# ESP32-S31 register map
Vendor: ESPRESSIF SYSTEMS (SHANGHAI) CO., LTD.; Series: ESP32 S-Series; File version: 1
CPU: RV32IMAFC r0p0, little endian, no MPU, FPU, 0 interrupt priority bits
Address unit: 32 bits
Registers are 32-bit, read-write, reset 0x0 unless marked. A register's access mark holds for its fields unless they carry their own. Offsets are from the block's base; [hi:lo] are bit positions; {n}, {i} and the like mark numbered series.

## SPI0 (part 1 of 2) — SPI (Serial Peripheral Interface) Controller 0
Base 0x20500000
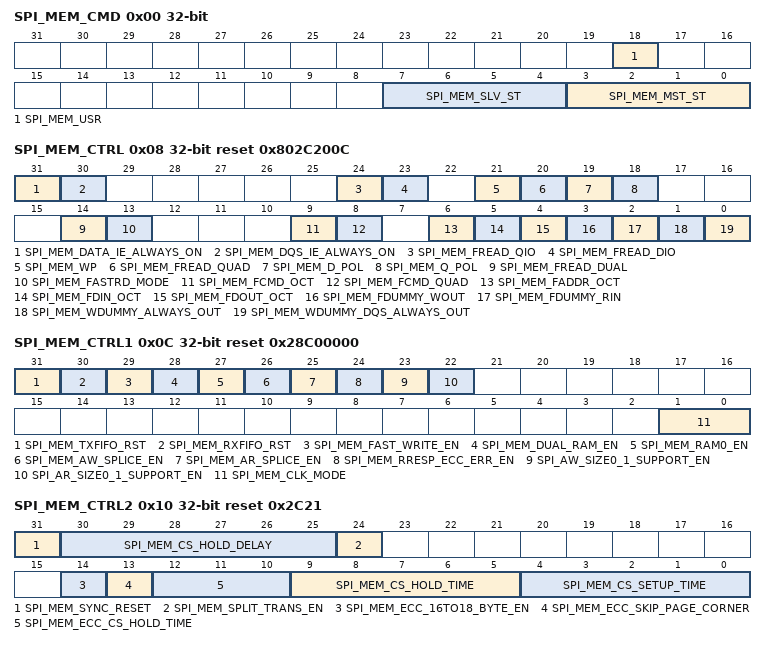
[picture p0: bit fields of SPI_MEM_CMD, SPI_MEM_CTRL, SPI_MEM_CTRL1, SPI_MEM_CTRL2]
0x00 SPI_MEM_CMD ro — SPI0 FSM status register
  [18] SPI_MEM_USR — SPI0 USR_CMD start bit, only used when SPI_MEM_AXI_REQ_EN is cleared. An operation will be triggered when the bit is set. The bit will be cleared once the operation done.1: enable 0: disable.
  [7:4] SPI_MEM_SLV_ST — The current status of SPI0 slave FSM: mspi_st. 0: idle state, 1: preparation state, 2: send command state, 3: send address state, 4: wait state, 5: read data state, 6:write data state, 7: done state, 8: read data end state.
  [3:0] SPI_MEM_MST_ST — The current status of SPI0 master FSM: spi0_mst_st. 0: idle state, 1:SPI0_GRANT , 2: program/erase suspend state, 3: SPI0 read data state, 4: wait cache/EDMA sent data is stored in SPI0 TX FIFO, 5: SPI0 write data state.
0x08 SPI_MEM_CTRL reset 0x802C200C — SPI0 control register.
  [31] SPI_MEM_DATA_IE_ALWAYS_ON — When accesses to flash, 1: the IE signals of pads connected to SPI_IO[7:0] are always 1. 0: Others.
  [30] SPI_MEM_DQS_IE_ALWAYS_ON — When accesses to flash, 1: the IE signals of pads connected to SPI_DQS are always 1. 0: Others.
  [24] SPI_MEM_FREAD_QIO — In the read operations address phase and read-data phase apply 4 signals. 1: enable 0: disable.
  [23] SPI_MEM_FREAD_DIO — In the read operations address phase and read-data phase apply 2 signals. 1: enable 0: disable.
  [21] SPI_MEM_WP — Write protect signal output when SPI is idle. 1: output high, 0: output low.
  [20] SPI_MEM_FREAD_QUAD — In the read operations read-data phase apply 4 signals. 1: enable 0: disable.
  [19] SPI_MEM_D_POL — The bit is used to set MOSI line polarity, 1: high 0, low
  [18] SPI_MEM_Q_POL — The bit is used to set MISO line polarity, 1: high 0, low
  [14] SPI_MEM_FREAD_DUAL — In the read operations, read-data phase apply 2 signals. 1: enable 0: disable.
  [13] SPI_MEM_FASTRD_MODE — This bit enable the bits: SPI_MEM_FREAD_QIO, SPI_MEM_FREAD_DIO, SPI_MEM_FREAD_QOUT and SPI_MEM_FREAD_DOUT. 1: enable 0: disable.
  [9] SPI_MEM_FCMD_OCT — Apply 8 signals during command phase 1:enable 0: disable
  [8] SPI_MEM_FCMD_QUAD — Apply 4 signals during command phase 1:enable 0: disable
  [6] SPI_MEM_FADDR_OCT — Apply 8 signals during address phase 1:enable 0: disable
  [5] SPI_MEM_FDIN_OCT — Apply 8 signals during read-data phase 1:enable 0: disable
  [4] SPI_MEM_FDOUT_OCT — Apply 8 signals during write-data phase 1:enable 0: disable
  [3] SPI_MEM_FDUMMY_WOUT — In an MSPI write data transfer when accesses to flash, the level of SPI_IO[7:0] is output by the MSPI controller in the second half part of dummy phase. It is used to pre-drive flash.
  [2] SPI_MEM_FDUMMY_RIN — In an MSPI read data transfer when accesses to flash, the level of SPI_IO[7:0] is output by the MSPI controller in the first half part of dummy phase. It is used to mask invalid SPI_DQS in the half part of dummy phase.
  [1] SPI_MEM_WDUMMY_ALWAYS_OUT — In the dummy phase of an MSPI write data transfer when accesses to flash, the level of SPI_IO[7:0] is output by the MSPI controller.
  [0] SPI_MEM_WDUMMY_DQS_ALWAYS_OUT — In the dummy phase of an MSPI write data transfer when accesses to flash, the level of SPI_DQS is output by the MSPI controller.
0x0C SPI_MEM_CTRL1 access per field reset 0x28C00000 — SPI0 control1 register.
  [31] SPI_MEM_TXFIFO_RST wo — The synchronous reset signal for SPI0 TX AFIFO and all the AES_MSPI SYNC FIFO to send signals to AXI. Set this bit to reset these FIFO.
  [30] SPI_MEM_RXFIFO_RST wo — The synchronous reset signal for SPI0 RX AFIFO and all the AES_MSPI SYNC FIFO to receive signals from AXI. Set this bit to reset these FIFO.
  [29] SPI_MEM_FAST_WRITE_EN rw — Set this bit to write data faster, do not wait write data has been stored in tx_bus_fifo_l2. It will wait 4*T_clk_ctrl to insure the write data has been stored in tx_bus_fifo_l2.
  [28] SPI_MEM_DUAL_RAM_EN ro — Set this bit to enable DUAL-RAM mode, EXT_RAM0 and EXT_RAM1 will be accessed at the same time.
  [27] SPI_MEM_RAM0_EN ro — When SPI_MEM_DUAL_RAM_EN is 0 and SPI_MEM_RAM0_EN is 1, only EXT_RAM0 will be accessed. When SPI_MEM_DUAL_RAM_EN is 0 and SPI_MEM_RAM0_EN is 0, only EXT_RAM1 will be accessed. When SPI_MEM_DUAL_RAM_EN is 1, EXT_RAM0 and EXT_RAM1 will be accessed at the same time.
  [26] SPI_MEM_AW_SPLICE_EN rw — Set this bit to enable AXI Write Splice-transfer.
  [25] SPI_MEM_AR_SPLICE_EN rw — Set this bit to enable AXI Read Splice-transfer.
  [24] SPI_MEM_RRESP_ECC_ERR_EN rw — 1: RRESP is SLV_ERR when there is a ECC error in AXI read data. 0: RRESP is OKAY when there is a ECC error in AXI read data. The ECC error information is recorded in SPI_MEM_ECC_ERR_ADDR_REG.
  [23] SPI_AW_SIZE0_1_SUPPORT_EN rw — 1: MSPI supports AWSIZE 0~3. 0: When AWSIZE 0~1, MSPI reply SLV_ERR.
  [22] SPI_AR_SIZE0_1_SUPPORT_EN rw — 1: MSPI supports ARSIZE 0~3. When ARSIZE =0~2, MSPI read address is 4*n and reply the real AXI read data back. 0: When ARSIZE 0~1, MSPI reply SLV_ERR.
  [1:0] SPI_MEM_CLK_MODE rw — SPI clock mode bits. 0: SPI clock is off when CS inactive 1: SPI clock is delayed one cycle after CS inactive 2: SPI clock is delayed two cycles after CS inactive 3: SPI clock is alwasy on.
0x10 SPI_MEM_CTRL2 access per field reset 0x2C21 — SPI0 control2 register.
  [31] SPI_MEM_SYNC_RESET wo — The spi0_mst_st and spi0_slv_st will be reset.
  [30:25] SPI_MEM_CS_HOLD_DELAY rw — These bits are used to set the minimum CS high time tSHSL between SPI burst transfer when accesses to flash. tSHSL is (SPI_MEM_CS_HOLD_DELAY[5:0] + 1) MSPI core clock cycles.
  [24] SPI_MEM_SPLIT_TRANS_EN rw — Set this bit to enable SPI0 split one AXI read flash transfer into two SPI transfers when one transfer will cross flash or EXT_RAM page corner, valid no matter whether there is an ECC region or not.
  [14] SPI_MEM_ECC_16TO18_BYTE_EN rw — Set this bit to enable SPI0 and SPI1 ECC 16 bytes data with 2 ECC bytes mode when accesses flash.
  [13] SPI_MEM_ECC_SKIP_PAGE_CORNER rw — 1: SPI0 and SPI1 skip page corner when accesses flash. 0: Not skip page corner when accesses flash.
  [12:10] SPI_MEM_ECC_CS_HOLD_TIME rw — SPI_MEM_CS_HOLD_TIME + SPI_MEM_ECC_CS_HOLD_TIME is the SPI0 CS hold cycle in ECC mode when accessed flash.
  [9:5] SPI_MEM_CS_HOLD_TIME rw — SPI CS signal is delayed to inactive by SPI bus clock, this bits are combined with SPI_MEM_CS_HOLD bit.
  [4:0] SPI_MEM_CS_SETUP_TIME rw — (cycles-1) of prepare phase by SPI Bus clock, this bits are combined with SPI_MEM_CS_SETUP bit.
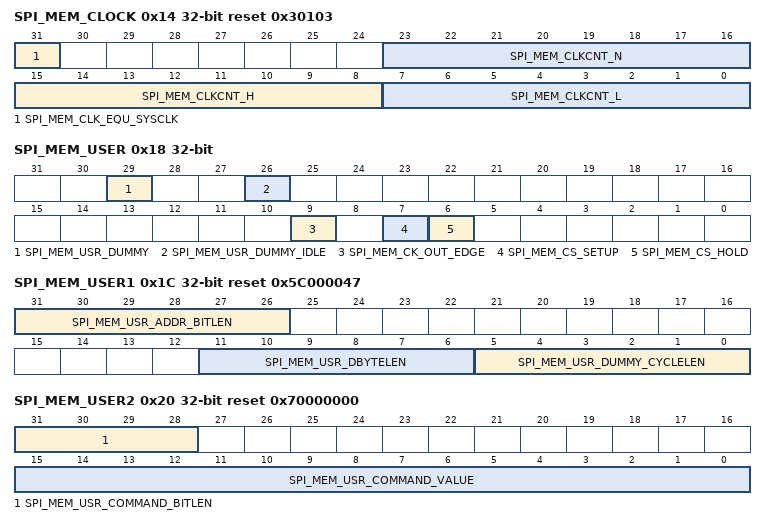
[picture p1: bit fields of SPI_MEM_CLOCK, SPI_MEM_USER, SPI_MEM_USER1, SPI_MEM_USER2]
0x14 SPI_MEM_CLOCK reset 0x30103 — SPI clock division control register.
  [31] SPI_MEM_CLK_EQU_SYSCLK — 1: 1-division mode, the frequency of SPI bus clock equals to that of MSPI module clock.
  [23:16] SPI_MEM_CLKCNT_N — In the master mode it is the divider of spi_mem_clk. So spi_mem_clk frequency is system/(SPI_MEM_CLKCNT_N+1)
  [15:8] SPI_MEM_CLKCNT_H — In the master mode it must be floor((SPI_MEM_CLKCNT_N+1)/2-1).
  [7:0] SPI_MEM_CLKCNT_L — In the master mode it must be equal to SPI_MEM_CLKCNT_N.
0x18 SPI_MEM_USER — SPI0 user register.
  [29] SPI_MEM_USR_DUMMY — This bit enable the dummy phase of an operation.
  [26] SPI_MEM_USR_DUMMY_IDLE — spi clock is disable in dummy phase when the bit is enable.
  [9] SPI_MEM_CK_OUT_EDGE — The bit combined with SPI_MEM_CK_IDLE_EDGE bit to control SPI clock mode 0~3.
  [7] SPI_MEM_CS_SETUP — spi cs is enable when spi is in prepare phase. 1: enable 0: disable.
  [6] SPI_MEM_CS_HOLD — spi cs keep low when spi is in done phase. 1: enable 0: disable.
0x1C SPI_MEM_USER1 access per field reset 0x5C000047 — SPI0 user1 register.
  [31:26] SPI_MEM_USR_ADDR_BITLEN rw — The length in bits of address phase. The register value shall be (bit_num-1).
  [11:6] SPI_MEM_USR_DBYTELEN ro — SPI0 USR_CMD read or write data byte length -1
  [5:0] SPI_MEM_USR_DUMMY_CYCLELEN rw — The length in spi_mem_clk cycles of dummy phase. The register value shall be (cycle_num-1).
0x20 SPI_MEM_USER2 reset 0x70000000 — SPI0 user2 register.
  [31:28] SPI_MEM_USR_COMMAND_BITLEN — The length in bits of command phase. The register value shall be (bit_num-1)
  [15:0] SPI_MEM_USR_COMMAND_VALUE — The value of command.
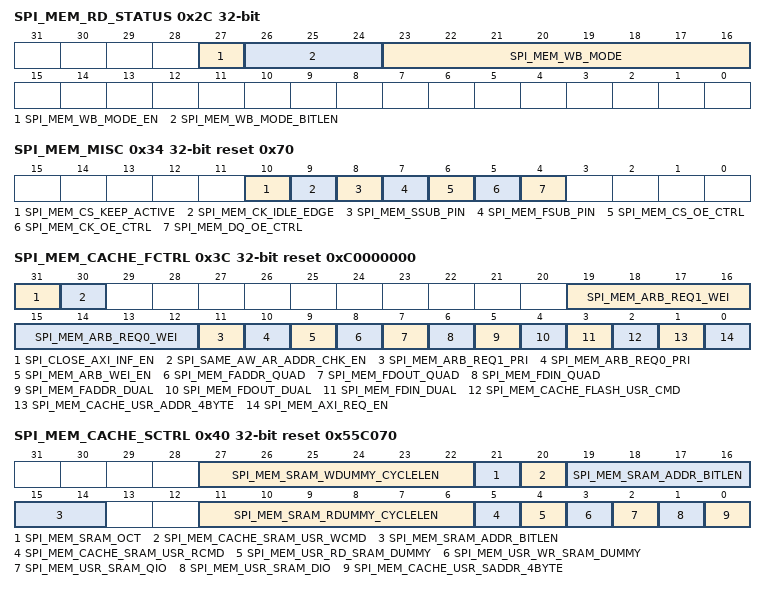
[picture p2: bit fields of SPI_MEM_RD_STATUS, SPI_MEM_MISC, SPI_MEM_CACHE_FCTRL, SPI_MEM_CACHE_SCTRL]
0x2C SPI_MEM_RD_STATUS — SPI0 read control register.
  [27] SPI_MEM_WB_MODE_EN — Mode bits is valid while this bit is enable. 1: enable 0: disable.
  [26:24] SPI_MEM_WB_MODE_BITLEN — Mode bits length for flash fast read mode.
  [23:16] SPI_MEM_WB_MODE — Mode bits in the flash fast read mode it is combined with spi_mem_fastrd_mode bit.
0x34 SPI_MEM_MISC access per field reset 0x70 — SPI0 misc register
  [10] SPI_MEM_CS_KEEP_ACTIVE rw — SPI_CS line keep low when the bit is set.
  [9] SPI_MEM_CK_IDLE_EDGE rw — 1: SPI_CLK line is high when idle 0: spi clk line is low when idle
  [8] SPI_MEM_SSUB_PIN ro — For SPI0, sram is connected to SUBPINs.
  [7] SPI_MEM_FSUB_PIN ro — For SPI0, flash is connected to SUBPINs.
  [6] SPI_MEM_CS_OE_CTRL rw — For SPI BUS IO, APB ctrl IO CS OE func.1: enable 0: disable.
  [5] SPI_MEM_CK_OE_CTRL rw — For SPI BUS IO, APB ctrl IO CK OE func.1: enable 0: disable.
  [4] SPI_MEM_DQ_OE_CTRL rw — For SPI BUS IO, APB ctrl IO DQ OE func.1: enable 0: disable.
0x3C SPI_MEM_CACHE_FCTRL reset 0xC0000000 — SPI0 bit mode control register.
  [31] SPI_CLOSE_AXI_INF_EN — Set this bit to close AXI read/write transfer to MSPI, which means that only SLV_ERR will be replied to BRESP/RRESP.
  [30] SPI_SAME_AW_AR_ADDR_CHK_EN — Set this bit to check AXI read/write the same address region.
  [19:16] SPI_MEM_ARB_REQ1_WEI — To set AXI write priority weight in SPI0 arbiter. While the priority are same, the larger the value, the greater the weight.
  [15:12] SPI_MEM_ARB_REQ0_WEI — To set AXI read priority weight in SPI0 arbiter. While the priority are same, the larger the value, the greater the weight.
  [11] SPI_MEM_ARB_REQ1_PRI — To set AXI write priority in SPI0 arbiter. The larger the value, the greater the priority.
  [10] SPI_MEM_ARB_REQ0_PRI — To set AXI read priority in SPI0 arbiter. The larger the value, the greater the priority.
  [9] SPI_MEM_ARB_WEI_EN — To enable SPI0 arbiter weight func while AXI read/write access SPI0 1: enable 0: disable.
  [8] SPI_MEM_FADDR_QUAD — For SPI0 flash, address phase apply 4 signals. 1: enable 0: disable. The bit is the same with spi_mem_fread_qio.
  [7] SPI_MEM_FDOUT_QUAD — For SPI0 flash, dout phase apply 4 signals. 1: enable 0: disable. The bit is the same with spi_mem_fread_qio.
  [6] SPI_MEM_FDIN_QUAD — For SPI0 flash, din phase apply 4 signals. 1: enable 0: disable. The bit is the same with spi_mem_fread_qio.
  [5] SPI_MEM_FADDR_DUAL — For SPI0 flash, address phase apply 2 signals. 1: enable 0: disable. The bit is the same with spi_mem_fread_dio.
  [4] SPI_MEM_FDOUT_DUAL — For SPI0 flash, dout phase apply 2 signals. 1: enable 0: disable. The bit is the same with spi_mem_fread_dio.
  [3] SPI_MEM_FDIN_DUAL — For SPI0 flash, din phase apply 2 signals. 1: enable 0: disable. The bit is the same with spi_mem_fread_dio.
  [2] SPI_MEM_CACHE_FLASH_USR_CMD — For SPI0, cache read flash for user define command, 1: enable, 0:disable.
  [1] SPI_MEM_CACHE_USR_ADDR_4BYTE — For SPI0, cache read flash with 4 bytes address, 1: enable, 0:disable.
  [0] SPI_MEM_AXI_REQ_EN — For SPI0, AXI master access enable, 1: enable, 0:disable.
0x40 SPI_MEM_CACHE_SCTRL reset 0x55C070 — SPI0 external RAM control register
  [27:22] SPI_MEM_SRAM_WDUMMY_CYCLELEN — For SPI0, In the external RAM mode, it is the length in bits of write dummy phase. The register value shall be (bit_num-1).
  [21] SPI_MEM_SRAM_OCT — reserved
  [20] SPI_MEM_CACHE_SRAM_USR_WCMD — For SPI0, In the external RAM mode cache write sram for user define command
  [19:14] SPI_MEM_SRAM_ADDR_BITLEN — For SPI0, In the external RAM mode, it is the length in bits of address phase. The register value shall be (bit_num-1).
  [11:6] SPI_MEM_SRAM_RDUMMY_CYCLELEN — For SPI0, In the external RAM mode, it is the length in bits of read dummy phase. The register value shall be (bit_num-1).
  [5] SPI_MEM_CACHE_SRAM_USR_RCMD — For SPI0, In the external RAM mode cache read external RAM for user define command.
  [4] SPI_MEM_USR_RD_SRAM_DUMMY — For SPI0, In the external RAM mode, it is the enable bit of dummy phase for read operations.
  [3] SPI_MEM_USR_WR_SRAM_DUMMY — For SPI0, In the external RAM mode, it is the enable bit of dummy phase for write operations.
  [2] SPI_MEM_USR_SRAM_QIO — For SPI0, In the external RAM mode, spi quad I/O mode enable, 1: enable, 0:disable
  [1] SPI_MEM_USR_SRAM_DIO — For SPI0, In the external RAM mode, spi dual I/O mode enable, 1: enable, 0:disable
  [0] SPI_MEM_CACHE_USR_SADDR_4BYTE — For SPI0, In the external RAM mode, cache read flash with 4 bytes command, 1: enable, 0:disable.
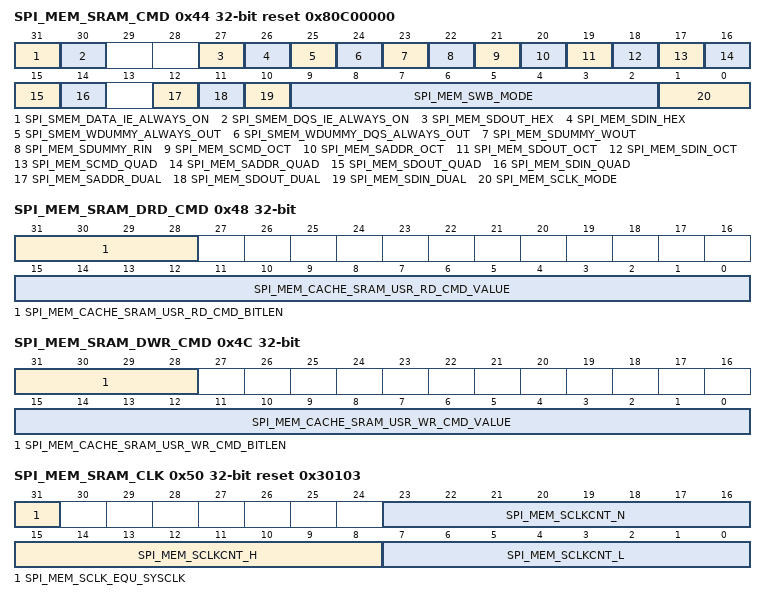
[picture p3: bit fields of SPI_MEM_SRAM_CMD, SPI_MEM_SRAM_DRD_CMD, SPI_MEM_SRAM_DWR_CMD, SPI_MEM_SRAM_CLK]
0x44 SPI_MEM_SRAM_CMD reset 0x80C00000 — SPI0 external RAM mode control register
  [31] SPI_SMEM_DATA_IE_ALWAYS_ON — When accesses to external RAM, 1: the IE signals of pads connected to SPI_IO[7:0] are always 1. 0: Others.
  [30] SPI_SMEM_DQS_IE_ALWAYS_ON — When accesses to external RAM, 1: the IE signals of pads connected to SPI_DQS are always 1. 0: Others.
  [27] SPI_MEM_SDOUT_HEX — For SPI0 external RAM , dout phase apply 16 signals. 1: enable 0: disable.
  [26] SPI_MEM_SDIN_HEX — For SPI0 external RAM , din phase apply 16 signals. 1: enable 0: disable.
  [25] SPI_SMEM_WDUMMY_ALWAYS_OUT — In the dummy phase of an MSPI write data transfer when accesses to external RAM, the level of SPI_IO[7:0] is output by the MSPI controller.
  [24] SPI_SMEM_WDUMMY_DQS_ALWAYS_OUT — In the dummy phase of an MSPI write data transfer when accesses to external RAM, the level of SPI_DQS is output by the MSPI controller.
  [23] SPI_MEM_SDUMMY_WOUT — In the dummy phase of a MSPI write data transfer when accesses to external RAM, the signal level of SPI bus is output by the MSPI controller.
  [22] SPI_MEM_SDUMMY_RIN — In the dummy phase of a MSPI read data transfer when accesses to external RAM, the signal level of SPI bus is output by the MSPI controller.
  [21] SPI_MEM_SCMD_OCT — For SPI0 external RAM , cmd phase apply 8 signals. 1: enable 0: disable.
  [20] SPI_MEM_SADDR_OCT — For SPI0 external RAM , address phase apply 4 signals. 1: enable 0: disable.
  [19] SPI_MEM_SDOUT_OCT — For SPI0 external RAM , dout phase apply 8 signals. 1: enable 0: disable.
  [18] SPI_MEM_SDIN_OCT — For SPI0 external RAM , din phase apply 8 signals. 1: enable 0: disable.
  [17] SPI_MEM_SCMD_QUAD — For SPI0 external RAM , cmd phase apply 4 signals. 1: enable 0: disable. The bit is the same with spi_mem_usr_sram_qio.
  [16] SPI_MEM_SADDR_QUAD — For SPI0 external RAM , address phase apply 4 signals. 1: enable 0: disable. The bit is the same with spi_mem_usr_sram_qio.
  [15] SPI_MEM_SDOUT_QUAD — For SPI0 external RAM , dout phase apply 4 signals. 1: enable 0: disable. The bit is the same with spi_mem_usr_sram_qio.
  [14] SPI_MEM_SDIN_QUAD — For SPI0 external RAM , din phase apply 4 signals. 1: enable 0: disable. The bit is the same with spi_mem_usr_sram_qio.
  [12] SPI_MEM_SADDR_DUAL — For SPI0 external RAM , address phase apply 2 signals. 1: enable 0: disable. The bit is the same with spi_mem_usr_sram_dio.
  [11] SPI_MEM_SDOUT_DUAL — For SPI0 external RAM , dout phase apply 2 signals. 1: enable 0: disable. The bit is the same with spi_mem_usr_sram_dio.
  [10] SPI_MEM_SDIN_DUAL — For SPI0 external RAM , din phase apply 2 signals. 1: enable 0: disable. The bit is the same with spi_mem_usr_sram_dio.
  [9:2] SPI_MEM_SWB_MODE — Mode bits in the external RAM fast read mode it is combined with spi_mem_fastrd_mode bit.
  [1:0] SPI_MEM_SCLK_MODE — SPI clock mode bits. 0: SPI clock is off when CS inactive 1: SPI clock is delayed one cycle after CS inactive 2: SPI clock is delayed two cycles after CS inactive 3: SPI clock is always on.
0x48 SPI_MEM_SRAM_DRD_CMD — SPI0 external RAM DDR read command control register
  [31:28] SPI_MEM_CACHE_SRAM_USR_RD_CMD_BITLEN — For SPI0,When cache mode is enable it is the length in bits of command phase for sram. The register value shall be (bit_num-1).
  [15:0] SPI_MEM_CACHE_SRAM_USR_RD_CMD_VALUE — For SPI0,When cache mode is enable it is the read command value of command phase for sram.
0x4C SPI_MEM_SRAM_DWR_CMD — SPI0 external RAM DDR write command control register
  [31:28] SPI_MEM_CACHE_SRAM_USR_WR_CMD_BITLEN — For SPI0,When cache mode is enable it is the in bits of command phase for sram. The register value shall be (bit_num-1).
  [15:0] SPI_MEM_CACHE_SRAM_USR_WR_CMD_VALUE — For SPI0,When cache mode is enable it is the write command value of command phase for sram.
0x50 SPI_MEM_SRAM_CLK reset 0x30103 — SPI0 external RAM clock control register
  [31] SPI_MEM_SCLK_EQU_SYSCLK — For SPI0 external RAM interface, 1: spi_mem_clk is eqaul to system 0: spi_mem_clk is divided from system clock.
  [23:16] SPI_MEM_SCLKCNT_N — For SPI0 external RAM interface, it is the divider of spi_mem_clk. So spi_mem_clk frequency is system/(SPI_MEM_SCLKCNT_N+1)
  [15:8] SPI_MEM_SCLKCNT_H — For SPI0 external RAM interface, it must be floor((SPI_MEM_SCLKCNT_N+1)/2-1).
  [7:0] SPI_MEM_SCLKCNT_L — For SPI0 external RAM interface, it must be equal to SPI_MEM_SCLKCNT_N.
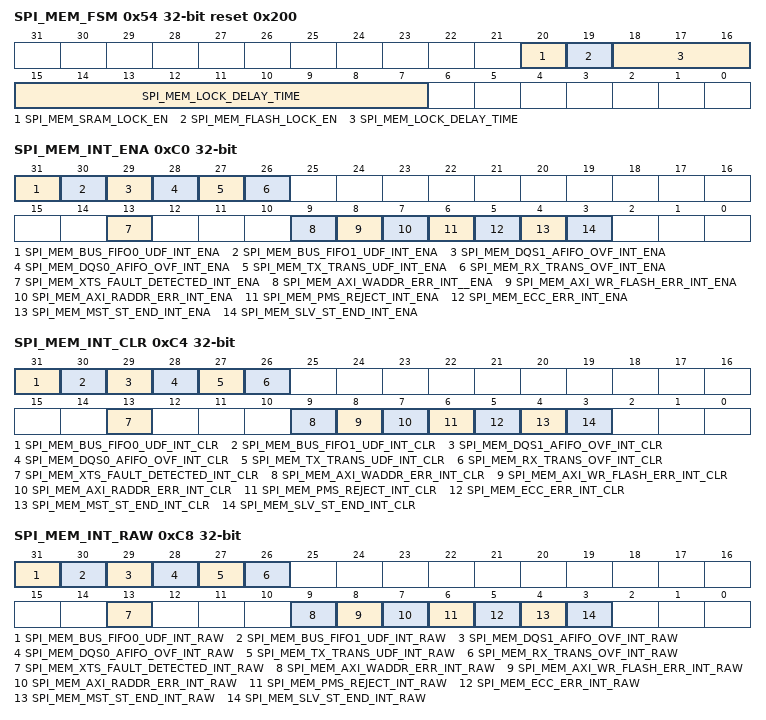
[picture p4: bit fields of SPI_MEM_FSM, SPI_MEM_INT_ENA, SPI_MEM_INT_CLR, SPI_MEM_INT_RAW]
0x54 SPI_MEM_FSM reset 0x200 — SPI0 FSM status register
  [20] SPI_MEM_SRAM_LOCK_EN — The lock enable for external RAM to lock spi0 trans req.1: Enable. 0: Disable.
  [19] SPI_MEM_FLASH_LOCK_EN — The lock enable for FLASH to lock spi0 trans req.1: Enable. 0: Disable.
  [18:7] SPI_MEM_LOCK_DELAY_TIME — The lock delay time of SPI0/1 arbiter by spi0_slv_st, after PER is sent by SPI1.
0xC0 SPI_MEM_INT_ENA — SPI0 interrupt enable register
  [31] SPI_MEM_BUS_FIFO0_UDF_INT_ENA — The enable bit for SPI_MEM_BUS_FIFO0_UDF_INT interrupt.
  [30] SPI_MEM_BUS_FIFO1_UDF_INT_ENA — The enable bit for SPI_MEM_BUS_FIFO1_UDF_INT interrupt.
  [29] SPI_MEM_DQS1_AFIFO_OVF_INT_ENA — The enable bit for SPI_MEM_DQS1_AFIFO_OVF_INT interrupt.
  [28] SPI_MEM_DQS0_AFIFO_OVF_INT_ENA — The enable bit for SPI_MEM_DQS0_AFIFO_OVF_INT interrupt.
  [27] SPI_MEM_TX_TRANS_UDF_INT_ENA — The enable bit for SPI_MEM_TX_TRANS_UDF_INT interrupt.
  [26] SPI_MEM_RX_TRANS_OVF_INT_ENA — The enable bit for SPI_MEM_RX_TRANS_OVF_INT interrupt.
  [13] SPI_MEM_XTS_FAULT_DETECTED_INT_ENA — The enable bit for SPI_MEM_XTS_FAULT_DETECTED_INT interrupt.
  [9] SPI_MEM_AXI_WADDR_ERR_INT__ENA — The enable bit for SPI_MEM_AXI_WADDR_ERR_INT interrupt.
  [8] SPI_MEM_AXI_WR_FLASH_ERR_INT_ENA — The enable bit for SPI_MEM_AXI_WR_FALSH_ERR_INT interrupt.
  [7] SPI_MEM_AXI_RADDR_ERR_INT_ENA — The enable bit for SPI_MEM_AXI_RADDR_ERR_INT interrupt.
  [6] SPI_MEM_PMS_REJECT_INT_ENA — The enable bit for SPI_MEM_PMS_REJECT_INT interrupt.
  [5] SPI_MEM_ECC_ERR_INT_ENA — The enable bit for SPI_MEM_ECC_ERR_INT interrupt.
  [4] SPI_MEM_MST_ST_END_INT_ENA — The enable bit for SPI_MEM_MST_ST_END_INT interrupt.
  [3] SPI_MEM_SLV_ST_END_INT_ENA — The enable bit for SPI_MEM_SLV_ST_END_INT interrupt.
0xC4 SPI_MEM_INT_CLR wo — SPI0 interrupt clear register
  [31] SPI_MEM_BUS_FIFO0_UDF_INT_CLR — The clear bit for SPI_MEM_BUS_FIFO0_UDF_INT interrupt.
  [30] SPI_MEM_BUS_FIFO1_UDF_INT_CLR — The clear bit for SPI_MEM_BUS_FIFO1_UDF_INT interrupt.
  [29] SPI_MEM_DQS1_AFIFO_OVF_INT_CLR — The clear bit for SPI_MEM_DQS1_AFIFO_OVF_INT interrupt.
  [28] SPI_MEM_DQS0_AFIFO_OVF_INT_CLR — The clear bit for SPI_MEM_DQS0_AFIFO_OVF_INT interrupt.
  [27] SPI_MEM_TX_TRANS_UDF_INT_CLR — The clear bit for SPI_MEM_TX_TRANS_UDF_INT interrupt.
  [26] SPI_MEM_RX_TRANS_OVF_INT_CLR — The clear bit for SPI_MEM_RX_TRANS_OVF_INT interrupt.
  [13] SPI_MEM_XTS_FAULT_DETECTED_INT_CLR — The clear bit for SPI_MEM_XTS_FAULT_DETECTED_INT interrupt.
  [9] SPI_MEM_AXI_WADDR_ERR_INT_CLR — The clear bit for SPI_MEM_AXI_WADDR_ERR_INT interrupt.
  [8] SPI_MEM_AXI_WR_FLASH_ERR_INT_CLR — The clear bit for SPI_MEM_AXI_WR_FALSH_ERR_INT interrupt.
  [7] SPI_MEM_AXI_RADDR_ERR_INT_CLR — The clear bit for SPI_MEM_AXI_RADDR_ERR_INT interrupt.
  [6] SPI_MEM_PMS_REJECT_INT_CLR — The clear bit for SPI_MEM_PMS_REJECT_INT interrupt.
  [5] SPI_MEM_ECC_ERR_INT_CLR — The clear bit for SPI_MEM_ECC_ERR_INT interrupt.
  [4] SPI_MEM_MST_ST_END_INT_CLR — The clear bit for SPI_MEM_MST_ST_END_INT interrupt.
  [3] SPI_MEM_SLV_ST_END_INT_CLR — The clear bit for SPI_MEM_SLV_ST_END_INT interrupt.
0xC8 SPI_MEM_INT_RAW — SPI0 interrupt raw register
  [31] SPI_MEM_BUS_FIFO0_UDF_INT_RAW — The raw bit for SPI_MEM_BUS_FIFO0_UDF_INT interrupt. 1: Triggered when BUS0 FIFO is underflow.
  [30] SPI_MEM_BUS_FIFO1_UDF_INT_RAW — The raw bit for SPI_MEM_BUS_FIFO1_UDF_INT interrupt. 1: Triggered when BUS1 FIFO is underflow.
  [29] SPI_MEM_DQS1_AFIFO_OVF_INT_RAW — The raw bit for SPI_MEM_DQS1_AFIFO_OVF_INT interrupt. 1: Triggered when the AFIFO connected to SPI_DQS is overflow.
  [28] SPI_MEM_DQS0_AFIFO_OVF_INT_RAW — The raw bit for SPI_MEM_DQS0_AFIFO_OVF_INT interrupt. 1: Triggered when the AFIFO connected to SPI_DQS1 is overflow.
  [27] SPI_MEM_TX_TRANS_UDF_INT_RAW — The raw bit for SPI_MEM_TX_TRANS_UDF_INT interrupt. 1: Triggered when the tx fifo to spi bus is underflow.
  [26] SPI_MEM_RX_TRANS_OVF_INT_RAW — The raw bit for SPI_MEM_RX_TRANS_OVF_INT interrupt. 1: Triggered when the rx fifo to spi bus is overrflow.
  [13] SPI_MEM_XTS_FAULT_DETECTED_INT_RAW — The raw bit for SPI_MEM_XTS_FAULT_DETECTED_INT interrupt. 1: Triggered when xts aes core detected fault injection attack. 0: Others.
  [9] SPI_MEM_AXI_WADDR_ERR_INT_RAW — The raw bit for SPI_MEM_AXI_WADDR_ERR_INT interrupt. 1: Triggered when AXI write address is invalid by compared to MMU configuration. 0: Others.
  [8] SPI_MEM_AXI_WR_FLASH_ERR_INT_RAW — The raw bit for SPI_MEM_AXI_WR_FALSH_ERR_INT interrupt. 1: Triggered when AXI write flash request is received. 0: Others.
  [7] SPI_MEM_AXI_RADDR_ERR_INT_RAW — The raw bit for SPI_MEM_AXI_RADDR_ERR_INT interrupt. 1: Triggered when AXI read address is invalid by compared to MMU configuration. 0: Others.
  [6] SPI_MEM_PMS_REJECT_INT_RAW — The raw bit for SPI_MEM_PMS_REJECT_INT interrupt. 1: Triggered when SPI1 access is rejected. 0: Others.
  [5] SPI_MEM_ECC_ERR_INT_RAW — The raw bit for SPI_MEM_ECC_ERR_INT interrupt. When SPI_FMEM_ECC_ERR_INT_EN is set and SPI_SMEM_ECC_ERR_INT_EN is cleared, this bit is triggered when the error times of SPI0/1 ECC read flash are equal or bigger than SPI_MEM_ECC_ERR_INT_NUM. When SPI_FMEM_ECC_ERR_INT_EN is cleared and SPI_SMEM_ECC_ERR_INT_EN is set, this bit is triggered when the error times of SPI0/1 ECC read external RAM are equal or bigger than SPI_MEM_ECC_ERR_INT_NUM. When SPI_FMEM_ECC_ERR_INT_EN and SPI_SMEM_ECC_ERR_INT_EN are set, this bit is triggered when the total error times of SPI0/1 ECC read external RAM and flash are equal or bigger than SPI_MEM_ECC_ERR_INT_NUM. When SPI_FMEM_ECC_ERR_INT_EN and SPI_SMEM_ECC_ERR_INT_EN are cleared, this bit will not be triggered.
  [4] SPI_MEM_MST_ST_END_INT_RAW — The raw bit for SPI_MEM_MST_ST_END_INT interrupt. 1: Triggered when spi0_mst_st is changed from non idle state to idle state. 0: Others.
  [3] SPI_MEM_SLV_ST_END_INT_RAW — The raw bit for SPI_MEM_SLV_ST_END_INT interrupt. 1: Triggered when spi0_slv_st is changed from non idle state to idle state. It means that SPI_CS raises high. 0: Others
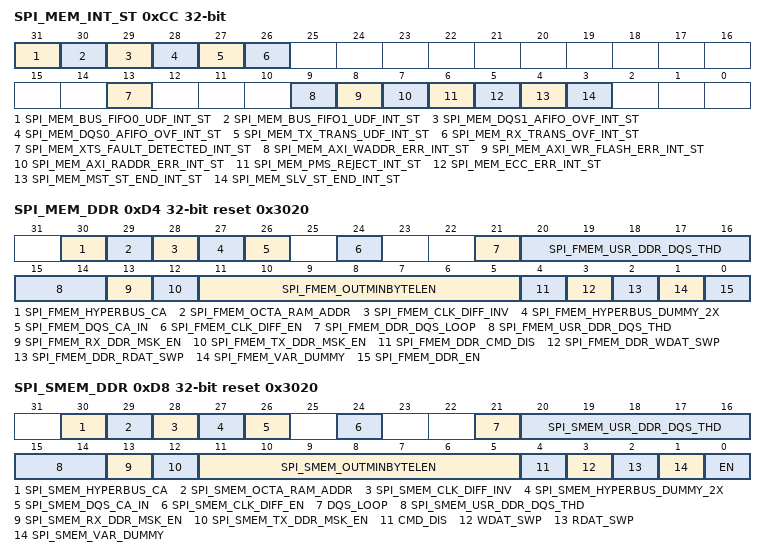
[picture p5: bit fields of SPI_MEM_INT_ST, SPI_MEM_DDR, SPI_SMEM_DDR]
0xCC SPI_MEM_INT_ST ro — SPI0 interrupt status register
  [31] SPI_MEM_BUS_FIFO0_UDF_INT_ST — The status bit for SPI_MEM_BUS_FIFO0_UDF_INT interrupt.
  [30] SPI_MEM_BUS_FIFO1_UDF_INT_ST — The status bit for SPI_MEM_BUS_FIFO1_UDF_INT interrupt.
  [29] SPI_MEM_DQS1_AFIFO_OVF_INT_ST — The status bit for SPI_MEM_DQS1_AFIFO_OVF_INT interrupt.
  [28] SPI_MEM_DQS0_AFIFO_OVF_INT_ST — The status bit for SPI_MEM_DQS0_AFIFO_OVF_INT interrupt.
  [27] SPI_MEM_TX_TRANS_UDF_INT_ST — The status bit for SPI_MEM_TX_TRANS_UDF_INT interrupt.
  [26] SPI_MEM_RX_TRANS_OVF_INT_ST — The status bit for SPI_MEM_RX_TRANS_OVF_INT interrupt.
  [13] SPI_MEM_XTS_FAULT_DETECTED_INT_ST — The status bit for SPI_MEM_XTS_FAULT_DETECTED_INT interrupt.
  [9] SPI_MEM_AXI_WADDR_ERR_INT_ST — The enable bit for SPI_MEM_AXI_WADDR_ERR_INT interrupt.
  [8] SPI_MEM_AXI_WR_FLASH_ERR_INT_ST — The enable bit for SPI_MEM_AXI_WR_FALSH_ERR_INT interrupt.
  [7] SPI_MEM_AXI_RADDR_ERR_INT_ST — The enable bit for SPI_MEM_AXI_RADDR_ERR_INT interrupt.
  [6] SPI_MEM_PMS_REJECT_INT_ST — The status bit for SPI_MEM_PMS_REJECT_INT interrupt.
  [5] SPI_MEM_ECC_ERR_INT_ST — The status bit for SPI_MEM_ECC_ERR_INT interrupt.
  [4] SPI_MEM_MST_ST_END_INT_ST — The status bit for SPI_MEM_MST_ST_END_INT interrupt.
  [3] SPI_MEM_SLV_ST_END_INT_ST — The status bit for SPI_MEM_SLV_ST_END_INT interrupt.
0xD4 SPI_MEM_DDR reset 0x3020 — SPI0 flash DDR mode control register
  [30] SPI_FMEM_HYPERBUS_CA — Set this bit to enable HyperRAM address out when accesses to flash, which means ADDR_OUT[31:0] = {spi_usr_addr_value[19:4], 13'd0, spi_usr_addr_value[3:1]}.
  [29] SPI_FMEM_OCTA_RAM_ADDR — Set this bit to enable octa_ram address out when accesses to flash, which means ADDR_OUT[31:0] = {spi_usr_addr_value[25:4], 6'd0, spi_usr_addr_value[3:1], 1'b0}.
  [28] SPI_FMEM_CLK_DIFF_INV — Set this bit to invert SPI_DIFF when accesses to flash. .
  [27] SPI_FMEM_HYPERBUS_DUMMY_2X — Set this bit to enable the vary dummy function in SPI HyperBus mode, when SPI0 accesses flash or SPI1 accesses flash or sram.
  [26] SPI_FMEM_DQS_CA_IN — Set this bit to enable the input of SPI_DQS signal in SPI phases of CMD and ADDR.
  [24] SPI_FMEM_CLK_DIFF_EN — Set this bit to enable the differential SPI_CLK#.
  [21] SPI_FMEM_DDR_DQS_LOOP — 1: Do not need the input of SPI_DQS signal, SPI0 starts to receive data when spi0_slv_st is in SPI_MEM_DIN state. It is used when there is no SPI_DQS signal or SPI_DQS signal is not stable. 0: SPI0 starts to store data at the positive and negative edge of SPI_DQS.
  [20:14] SPI_FMEM_USR_DDR_DQS_THD — The delay number of data strobe which from memory based on SPI clock.
  [13] SPI_FMEM_RX_DDR_MSK_EN — Set this bit to mask the first or the last byte in SPI0 ECC DDR read mode, when accesses to flash.
  [12] SPI_FMEM_TX_DDR_MSK_EN — Set this bit to mask the first or the last byte in SPI0 ECC DDR write mode, when accesses to flash.
  [11:5] SPI_FMEM_OUTMINBYTELEN — It is the minimum output data length in the panda device.
  [4] SPI_FMEM_DDR_CMD_DIS — the bit is used to disable dual edge in command phase when DDR mode.
  [3] SPI_FMEM_DDR_WDAT_SWP — Set the bit to reorder tx data of the word in spi DDR mode.
  [2] SPI_FMEM_DDR_RDAT_SWP — Set the bit to reorder rx data of the word in spi DDR mode.
  [1] SPI_FMEM_VAR_DUMMY — Set the bit to enable variable dummy cycle in spi DDR mode.
  [0] SPI_FMEM_DDR_EN — 1: in DDR mode, 0 in SDR mode
0xD8 SPI_SMEM_DDR reset 0x3020 — SPI0 external RAM DDR mode control register
  [30] SPI_SMEM_HYPERBUS_CA — Set this bit to enable HyperRAM address out when accesses to external RAM, which means ADDR_OUT[31:0] = {spi_usr_addr_value[19:4], 13'd0, spi_usr_addr_value[3:1]}.
  [29] SPI_SMEM_OCTA_RAM_ADDR — Set this bit to enable octa_ram address out when accesses to external RAM, which means ADDR_OUT[31:0] = {spi_usr_addr_value[25:4], 6'd0, spi_usr_addr_value[3:1], 1'b0}.
  [28] SPI_SMEM_CLK_DIFF_INV — Set this bit to invert SPI_DIFF when accesses to external RAM. .
  [27] SPI_SMEM_HYPERBUS_DUMMY_2X — Set this bit to enable the vary dummy function in SPI HyperBus mode, when SPI0 accesses flash or SPI1 accesses flash or sram.
  [26] SPI_SMEM_DQS_CA_IN — Set this bit to enable the input of SPI_DQS signal in SPI phases of CMD and ADDR.
  [24] SPI_SMEM_CLK_DIFF_EN — Set this bit to enable the differential SPI_CLK#.
  [21] DQS_LOOP — 1: Do not need the input of SPI_DQS signal, SPI0 starts to receive data when spi0_slv_st is in SPI_MEM_DIN state. It is used when there is no SPI_DQS signal or SPI_DQS signal is not stable. 0: SPI0 starts to store data at the positive and negative edge of SPI_DQS.
  [20:14] SPI_SMEM_USR_DDR_DQS_THD — The delay number of data strobe which from memory based on SPI clock.
  [13] SPI_SMEM_RX_DDR_MSK_EN — Set this bit to mask the first or the last byte in SPI0 ECC DDR read mode, when accesses to external RAM.
  [12] SPI_SMEM_TX_DDR_MSK_EN — Set this bit to mask the first or the last byte in SPI0 ECC DDR write mode, when accesses to external RAM.
  [11:5] SPI_SMEM_OUTMINBYTELEN — It is the minimum output data length in the DDR psram.
  [4] CMD_DIS — the bit is used to disable dual edge in command phase when DDR mode.
  [3] WDAT_SWP — Set the bit to reorder tx data of the word in spi DDR mode.
  [2] RDAT_SWP — Set the bit to reorder rx data of the word in spi DDR mode.
  [1] SPI_SMEM_VAR_DUMMY — Set the bit to enable variable dummy cycle in spi DDR mode.
  [0] EN — 1: in DDR mode, 0 in SDR mode
